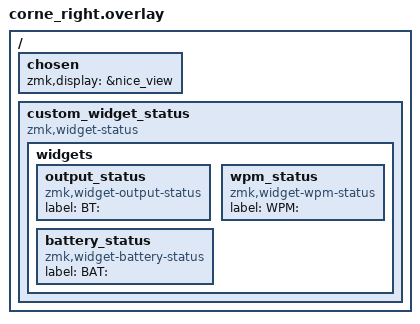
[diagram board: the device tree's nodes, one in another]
#include <dt-bindings/zmk/matrix_transform.h>

/ {
    chosen {
        zmk,display = &nice_view;
    };

    custom_widget_status {
        compatible = "zmk,widget-status";
        
        // Right side widgets
        widgets {
            output_status {
                compatible = "zmk,widget-output-status";
                label = "BT:";
            };
            
            battery_status {
                compatible = "zmk,widget-battery-status";
                label = "BAT:";
            };
            
            wpm_status {
                compatible = "zmk,widget-wpm-status";
                label = "WPM:";
            };
        };
    };
};
